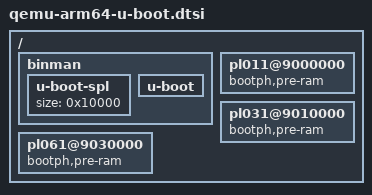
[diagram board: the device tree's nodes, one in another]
// SPDX-License-Identifier: GPL-2.0+ OR MIT
/*
 * Sample device tree for qemu_arm

 * Copyright 2021 Google LLC
 */

/ {
	binman {
		u-boot-spl {
			size = <0x10000>;
		};

		u-boot {
		};
	};

	pl011@9000000 {
		bootph,pre-ram;
	};

	pl031@9010000 {
		bootph,pre-ram;
	};

	pl061@9030000 {
		bootph,pre-ram;
	};
};
